AUTOSAR XML (schema 4-2-2)
package /Components
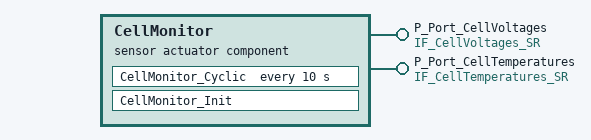
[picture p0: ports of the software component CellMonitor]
  sensor actuator sw component type CellMonitor
    provide port P_Port_CellVoltages: provided-interface=IF_CellVoltages_SR
    provide port P_Port_CellTemperatures: provided-interface=IF_CellTemperatures_SR
    behavior CellMonitor_InternalBehavior
      init event CellMonitor_Init_Event: start-on-event=CellMonitor_Init
      timing event CellMonitor_10ms_Event: start-on-event=CellMonitor_Cyclic, period=10
      runnable CellMonitor_Init
        data-send-points:
          4 x access:
            VA_Init_CellVoltages_Array: accessed-variable=P_Port_CellVoltages.CellVoltages_Array
            VA_Init_PackVoltage: accessed-variable=P_Port_CellVoltages.PackVoltage
            VA_Init_CellTemperatures_Array: accessed-variable=P_Port_CellTemperatures.CellTemperatures_Array
            VA_Init_PackTemperature: accessed-variable=P_Port_CellTemperatures.PackTemperature
      runnable CellMonitor_Cyclic: minimum-start-interval=10
        data-send-points:
          4 x access:
            VA_Cyc_CellVoltages_Array: accessed-variable=P_Port_CellVoltages.CellVoltages_Array
            VA_Cyc_PackVoltage: accessed-variable=P_Port_CellVoltages.PackVoltage
            VA_Cyc_CellTemperatures_Array: accessed-variable=P_Port_CellTemperatures.CellTemperatures_Array
            VA_Cyc_PackTemperature: accessed-variable=P_Port_CellTemperatures.PackTemperature
